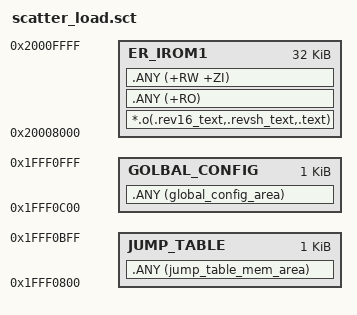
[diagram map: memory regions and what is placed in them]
; *************************************************************
; *** Scatter-Loading Description File generated by uVision ***
; *************************************************************

 LR_IROM1 0x20008000 0x00008000 {  ; load region size_region
  ER_IROM1 0x20008000 0x00008000  {  ; load address = execution address
   ;*.o (RESET, +First)
   *.o(.rev16_text,.revsh_text,.text)
   .ANY (+RO) 
   .ANY (+RW +ZI)
  }
  
  ;RW_IRAM1 0x20000000 0x00004000  {  ; RW data
  ;}
  ;ER_IROM2 0x1fff4100 0x0003500  {  ; load address = execution address
  ; .ANY (+RO) 
  ;}  
  
  ;RW_IRAM1 0x1fff7600 0x00000d00  {  ; RW data
  ; .ANY (+RW +ZI)
  ;}
 
}


 ;LR_IROM3 0x20008000 0x00008000 {  ; load region size_region
 ; ER_IROM3 0x20008000 0x00008000  {  ; load address = execution address
	
 ;  .ANY (dynamically_load_area)
 ;  ui_page.o
 ;  ui_128x32_normal.o
 ; }
 
;}

 
LR_IROM2  0x1fff0800 0x00800 {
  JUMP_TABLE 0x1fff0800 0x00400  {
   .ANY (jump_table_mem_area) 
	
  }
  GOLBAL_CONFIG 0x1fff0c00 0x00400  {
   .ANY (global_config_area) 
	
  }  
 } 



